VERSION ""

NS_ :

BS_:

BU_: Danfoss_Controller Headles_Pi Front_Display Side_Display Steering Column_Tilt Throttle_Actuator Lights Dyno_Cart Test_Stand CPP_Sled MP1_Actuator

BO_ 3221225472 VECTOR__INDEPENDENT_SIG_MSG: 0 Vector__XXX
 SG_ NewSignal_0005 : 32|8@1+ (1,0) [0|0] "" Vector__XXX
 SG_ NewSignal_0006 : 32|8@1+ (1,0) [0|0] "" Vector__XXX
 SG_ NewSignal_0011 : 32|1@1+ (1,0) [0|0] "" Vector__XXX
 SG_ NewSignal_0010 : 7|1@1+ (1,0) [0|0] "" Vector__XXX

BO_ 2365559670 Steering_Module_Position: 8 Steering
 SG_ Position : 0|8@1+ (1,0) [0|0] "" Vector__XXX
 SG_ speed : 8|8@1+ (1,0) [0|0] "" Vector__XXX

BO_ 2147483650 Steering_Feedback: 8 Danfoss_Controller

BO_ 2147483651 Ligh_Module_Control: 8 Vector__XXX

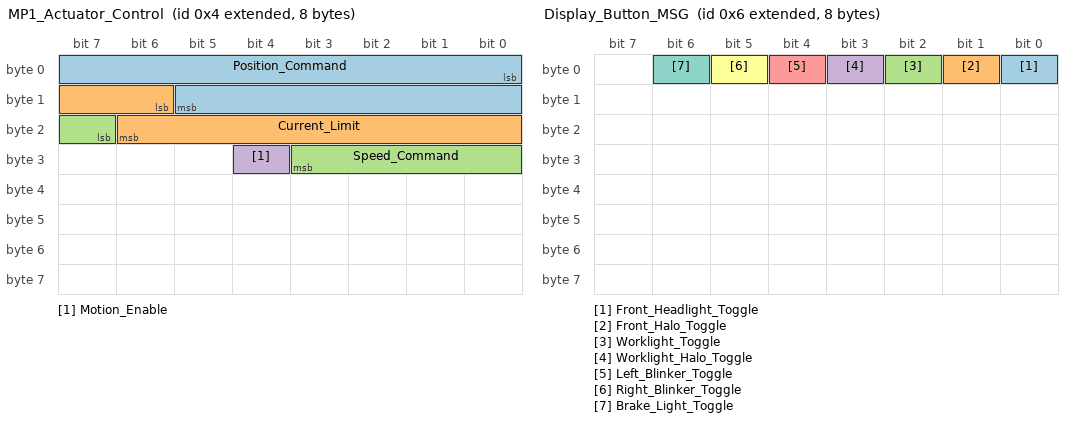
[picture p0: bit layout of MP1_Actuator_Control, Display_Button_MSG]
BO_ 2147483652 MP1_Actuator_Control: 8 Danfoss_Controller
 SG_ Position_Command : 0|14@1+ (1,0) [0|5000] "" Vector__XXX
 SG_ Current_Limit : 14|9@1+ (1,0) [0|0] "" Vector__XXX
 SG_ Speed_Command : 23|5@1+ (1,0) [0|0] "" Vector__XXX
 SG_ Motion_Enable : 28|1@1+ (1,0) [0|0] "" Vector__XXX

BO_ 2147483654 Display_Button_MSG: 8 Side_Display
 SG_ Front_Headlight_Toggle : 0|1@1+ (1,0) [0|0] "" Vector__XXX
 SG_ Front_Halo_Toggle : 1|1@1+ (1,0) [0|0] "" Vector__XXX
 SG_ Worklight_Toggle : 2|1@1+ (1,0) [0|0] "" Vector__XXX
 SG_ Worklight_Halo_Toggle : 3|1@1+ (1,0) [0|0] "" Vector__XXX
 SG_ Left_Blinker_Toggle : 4|1@1+ (1,0) [0|0] "" Vector__XXX
 SG_ Right_Blinker_Toggle : 5|1@1+ (1,0) [0|0] "" Vector__XXX
 SG_ Brake_Light_Toggle : 6|1@1+ (1,0) [0|0] "" Vector__XXX

CM_ BU_ MP1_Actuator "SA=27
";
CM_ BO_ 2365559670 "Steering Position from module";
CM_ BO_ 2147483650 "Feedback From Controller to Steering_Module";
CM_ BO_ 2147483651 "Control for Lights";
CM_ BO_ 2147483652 "Control Message for actuator";
CM_ BO_ 2147483654 "Button Presses from the side display";
